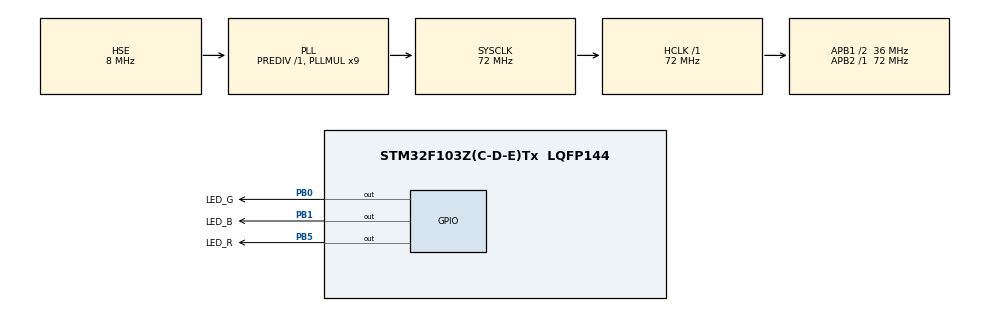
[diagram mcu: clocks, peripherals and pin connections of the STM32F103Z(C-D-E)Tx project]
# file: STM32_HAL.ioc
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Mcu.Family=STM32F1
Mcu.Name=STM32F103Z(C-D-E)Tx
Mcu.Package=LQFP144
NVIC.PriorityGroup=NVIC_PRIORITYGROUP_4
OSC_IN.Mode=HSE-External-Oscillator
OSC_IN.Signal=RCC_OSC_IN
OSC_OUT.Mode=HSE-External-Oscillator
OSC_OUT.Signal=RCC_OSC_OUT
PA13.Mode=JTAG_5_pins
PA13.Signal=SYS_JTMS-SWDIO
PA14.Mode=JTAG_5_pins
PA14.Signal=SYS_JTCK-SWCLK
PA15.Mode=JTAG_5_pins
PA15.Signal=SYS_JTDI
PB0.GPIO_Label=LED_G
PB0.GPIO_Speed=GPIO_SPEED_FREQ_HIGH
PB0.PinState=GPIO_PIN_SET
PB0.Signal=GPIO_Output
PB1.GPIO_Label=LED_B
PB1.GPIO_Speed=GPIO_SPEED_FREQ_HIGH
PB1.PinState=GPIO_PIN_SET
PB1.Signal=GPIO_Output
PB3.Mode=JTAG_5_pins
PB3.Signal=SYS_JTDO-TRACESWO
PB4.Mode=JTAG_5_pins
PB4.Signal=SYS_NJTRST
PB5.GPIO_Label=LED_R
PB5.GPIO_Speed=GPIO_SPEED_FREQ_HIGH
PB5.PinState=GPIO_PIN_SET
PB5.Signal=GPIO_Output
PC14-OSC32_IN.Mode=LSE-External-Oscillator
PC14-OSC32_IN.Signal=RCC_OSC32_IN
PC15-OSC32_OUT.Mode=LSE-External-Oscillator
PC15-OSC32_OUT.Signal=RCC_OSC32_OUT
ProjectManager.HeapSize=0x200
ProjectManager.StackSize=0x400
ProjectManager.TargetToolchain=CMake
RCC.AHBFreq_Value=72000000
RCC.APB1CLKDivider=RCC_HCLK_DIV2
RCC.APB1Freq_Value=36000000
RCC.APB1TimFreq_Value=72000000
RCC.APB2Freq_Value=72000000
RCC.APB2TimFreq_Value=72000000
RCC.HCLKFreq_Value=72000000
RCC.PLLMUL=RCC_PLL_MUL9
RCC.PLLSourceVirtual=RCC_PLLSOURCE_HSE
RCC.SYSCLKFreq_VALUE=72000000
RCC.SYSCLKSource=RCC_SYSCLKSOURCE_PLLCLK
RCC.USBFreq_Value=72000000
TIM6.Prescaler=72-1
VP_TIM6_VS_ClockSourceINT.Mode=Enable_Timer
board=custom

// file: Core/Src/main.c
/* USER CODE BEGIN Header */
/**
  ******************************************************************************
  * @file           : main.c
  * @brief          : Main program body
  ******************************************************************************
  * @attention
  *
  * Copyright (c) 2024 STMicroelectronics.
  * All rights reserved.
  *
  * This software is licensed under terms that can be found in the LICENSE file
  * in the root directory of this software component.
  * If no LICENSE file comes with this software, it is provided AS-IS.
  *
  ******************************************************************************
  */
/* USER CODE END Header */
#include "main.h"
#include "tim.h"
#include "gpio.h"

/* USER CODE BEGIN Includes */

#include <stdio.h>
#include "uart.h"
#include "my_dma.h"
#include "oled.h"
#include "delay.h"

#include "my_i2c.h"

/* USER CODE END Includes */

/* USER CODE BEGIN PM */

// R: PB5, G: PB0, B: PB1
#define LED_R 0xFFFFFFDF
#define LED_G 0xFFFFFFFE
#define LED_B 0xFFFFFFFD

/* USER CODE END PM */

/* USER CODE BEGIN PV */
uint32_t ledColorArray[] = {LED_R, LED_G, LED_B};
// static uint8_t ledColorIndex = 0;

extern UART_HandleTypeDef uart1Handle;
extern DMA_HandleTypeDef uart1RxDMAHandle;
uint8_t uartRecvBuf[256];
uint32_t count = 0;

/* USER CODE END PV */

void SystemClock_Config(void);

int main(void)
{

  /* MCU Configuration--------------------------------------------------------*/

  /* Reset of all peripherals, Initializes the Flash interface and the Systick. */
  HAL_Init();

  /* Configure the system clock */
  SystemClock_Config();

  /* Initialize all configured peripherals */
  MX_GPIO_Init();
  MX_TIM6_Init();
  /* USER CODE BEGIN 2 */

  // UART1 and DMA
  HAL_StatusTypeDef dmaInitStat = InitUART1DMA();
  InitBoardUART();

  // 启动delay用的定时
  HAL_TIM_Base_Start(&htim6);

  // OLED
  if (OLED_InitDisplay() < 0) {
    printf("init OLED screen failed!\r\n");
  } else {
    puts("OLED ok!");
  }

  /* USER CODE END 2 */

  /* Infinite loop */
  /* USER CODE BEGIN WHILE */

  puts("hello UARTx!");
  if (dmaInitStat == HAL_OK) {
    printf("DMA init success!\r\n");
  } else {
    printf("DMA init failed!\r\n");
  }

  __HAL_RCC_GPIOB_CLK_ENABLE();

  // recv data from UART in interrupt mode
  // HAL_UART_Receive_IT(&uart1Handle, uartRecvBuf, 16);

  // enable NVIC interrupt handle for USART1
  HAL_NVIC_SetPriority(USART1_IRQn, 5, 0);
  HAL_NVIC_EnableIRQ(USART1_IRQn);

  // enable NVIC interrupt handle for DMA1 rx
  HAL_NVIC_SetPriority(DMA1_Channel5_IRQn, 4, 0);
  HAL_NVIC_EnableIRQ(DMA1_Channel5_IRQn);

  // enable NVIC interrupt handle for DMA1 tx
  HAL_NVIC_SetPriority(DMA1_Channel4_IRQn, 4, 0);
  HAL_NVIC_EnableIRQ(DMA1_Channel4_IRQn);

  OLED_Test();

  // I2C_Test();

  while (1)
  {
    /* USER CODE END WHILE */

    /* USER CODE BEGIN 3 */
    GPIOB->ODR = LED_R;
    delay_ms(500);
    GPIOB->ODR = LED_G;
    delay_ms(500);
    GPIOB->ODR = LED_B;
    delay_ms(500);
  }
  /* USER CODE END 3 */
}

void SystemClock_Config(void)
{
  RCC_OscInitTypeDef RCC_OscInitStruct = {0};
  RCC_ClkInitTypeDef RCC_ClkInitStruct = {0};

  /** Initializes the RCC Oscillators according to the specified parameters
  * in the RCC_OscInitTypeDef structure.
  */
  RCC_OscInitStruct.OscillatorType = RCC_OSCILLATORTYPE_HSE;
  RCC_OscInitStruct.HSEState = RCC_HSE_ON;
  RCC_OscInitStruct.HSEPredivValue = RCC_HSE_PREDIV_DIV1;
  RCC_OscInitStruct.HSIState = RCC_HSI_ON;
  RCC_OscInitStruct.PLL.PLLState = RCC_PLL_ON;
  RCC_OscInitStruct.PLL.PLLSource = RCC_PLLSOURCE_HSE;
  RCC_OscInitStruct.PLL.PLLMUL = RCC_PLL_MUL9;
  if (HAL_RCC_OscConfig(&RCC_OscInitStruct) != HAL_OK)
  {
    Error_Handler();
  }

  /** Initializes the CPU, AHB and APB buses clocks
  */
  RCC_ClkInitStruct.ClockType = RCC_CLOCKTYPE_HCLK|RCC_CLOCKTYPE_SYSCLK
                              |RCC_CLOCKTYPE_PCLK1|RCC_CLOCKTYPE_PCLK2;
  RCC_ClkInitStruct.SYSCLKSource = RCC_SYSCLKSOURCE_PLLCLK;
  RCC_ClkInitStruct.AHBCLKDivider = RCC_SYSCLK_DIV1;
  RCC_ClkInitStruct.APB1CLKDivider = RCC_HCLK_DIV2;
  RCC_ClkInitStruct.APB2CLKDivider = RCC_HCLK_DIV1;

  if (HAL_RCC_ClockConfig(&RCC_ClkInitStruct, FLASH_LATENCY_2) != HAL_OK)
  {
    Error_Handler();
  }
}

/* USER CODE BEGIN 4 */
int __io_putchar(int ch)
{
    HAL_UART_Transmit(&uart1Handle, (uint8_t *)&ch, 1, HAL_MAX_DELAY);
    return 0;
}
/* USER CODE END 4 */

void Error_Handler(void)
{
  __disable_irq();
  while (1)
  {
  }
}
